AUTOSAR XML (schema 00051)
standard types defined: uint8
package /DataTypes
  app type DoorStateType: category=VALUE, base-type=uint8, compu {0=CLOSED, 1=OPEN, else CLOSED}
package /Interfaces
  sender receiver interface DoorState_IF
    data DoorState: type=DoorStateType
package /AppSwc
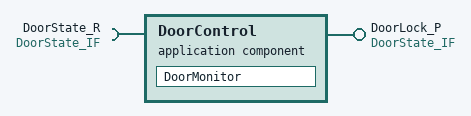
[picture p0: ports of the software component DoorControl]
  application sw component type DoorControl  # Door Control SWC
    require port DoorState_R: required-interface=DoorState_IF
    provide port DoorLock_P: provided-interface=DoorState_IF
    behavior DoorBehavior
      runnable DoorMonitor: symbol=DoorControl_Monitor, minimum-start-interval=0.01
